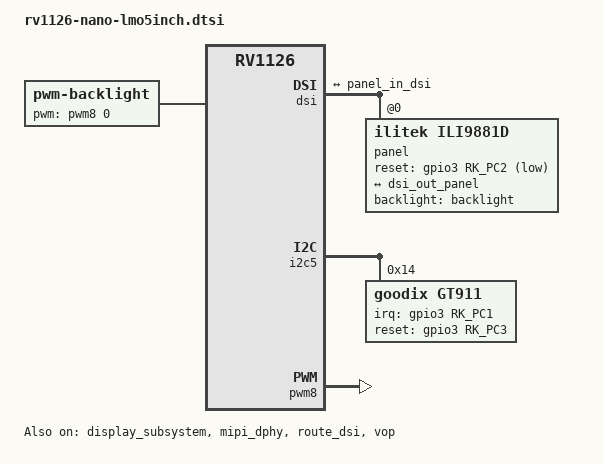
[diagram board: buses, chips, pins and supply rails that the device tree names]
// SPDX-License-Identifier: (GPL-2.0+ OR MIT)
/*
 * Guangzhou Easy EAI Technology Co., Ltd.
 *
 */

#include <dt-bindings/display/drm_mipi_dsi.h>

/ {
	backlight: backlight {
		compatible = "pwm-backlight";
		pwms = <&pwm8 0 25000 0>;
		brightness-levels = <
			  0   1   2   3   4   5   6   7
			  8   9  10  11  12  13  14  15
			 16  17  18  19  20  21  22  23
			 24  25  26  27  28  29  30  31
			 32  33  34  35  36  37  38  39
			 40  41  42  43  44  45  46  47
			 48  49  50  51  52  53  54  55
			 56  57  58  59  60  61  62  63
			 64  65  66  67  68  69  70  71
			 72  73  74  75  76  77  78  79
			 80  81  82  83  84  85  86  87
			 88  89  90  91  92  93  94  95
			 96  97  98  99 100 101 102 103
			104 105 106 107 108 109 110 111
			112 113 114 115 116 117 118 119
			120 121 122 123 124 125 126 127
			128 129 130 131 132 133 134 135
			136 137 138 139 140 141 142 143
			144 145 146 147 148 149 150 151
			152 153 154 155 156 157 158 159
			160 161 162 163 164 165 166 167
			168 169 170 171 172 173 174 175
			176 177 178 179 180 181 182 183
			184 185 186 187 188 189 190 191
			192 193 194 195 196 197 198 199
			200 201 202 203 204 205 206 207
			208 209 210 211 212 213 214 215
			216 217 218 219 220 221 222 223
			224 225 226 227 228 229 230 231
			232 233 234 235 236 237 238 239
			240 241 242 243 244 245 246 247
			248 249 250 251 252 253 254 255>;
		default-brightness-level = <255>;
	};
};

&display_subsystem {
	status = "okay";
};

&dsi {
	status = "okay";

	panel@0 {
		pinctrl-names = "default";
		pinctrl-0 = <&panel_rst>;
		compatible = "ilitek,ili9881d", "simple-panel-dsi";
		reg = <0>;
		backlight = <&backlight>;
		reset-gpios = <&gpio3 RK_PC2 GPIO_ACTIVE_LOW>;
		prepare-delay-ms = <5>;
		reset-delay-ms = <10>;
		init-delay-ms = <120>;

		width-mm = <61>;
		height-mm = <109>;

		dsi,flags = <(MIPI_DSI_MODE_VIDEO | MIPI_DSI_MODE_VIDEO_BURST |
			      MIPI_DSI_MODE_LPM | MIPI_DSI_MODE_EOT_PACKET)>;
		dsi,format = <MIPI_DSI_FMT_RGB888>;
		dsi,lanes = <4>;

		panel-init-sequence = [
			15 00 02 E1 93
			15 00 02 E2 65
			15 00 02 E3 F8
			15 00 02 70 20
			15 00 02 71 13
			15 00 02 72 06
			15 00 02 75 03
			15 00 02 E0 01
			15 00 02 00 00
			15 00 02 01 47
			15 00 02 03 00
			15 00 02 04 4D
			15 00 02 0C 64
			15 00 02 17 00
			15 00 02 18 BF
			15 00 02 19 00
			15 00 02 1A 00
			15 00 02 1B BF
			15 00 02 1C 00
			15 00 02 1F 7E
			15 00 02 20 24
			15 00 02 21 24
			15 00 02 22 4E
			15 00 02 24 FE
			15 00 02 37 09
			15 00 02 38 04
			15 00 02 3C 76
			15 00 02 3D FF
			15 00 02 3E FF
			15 00 02 3F 7F
			15 00 02 40 04
			15 00 02 41 A0
			15 00 02 44 11
			15 00 02 55 02
			15 00 02 56 01
			15 00 02 57 49
			15 00 02 58 09
			15 00 02 59 2A
			15 00 02 5A 1A
			15 00 02 5B 1A
			15 00 02 5D 78
			15 00 02 5E 6E
			15 00 02 5F 66
			15 00 02 60 5E
			15 00 02 61 60
			15 00 02 62 54
			15 00 02 63 5C
			15 00 02 64 47
			15 00 02 65 5F
			15 00 02 66 5D
			15 00 02 67 5B
			15 00 02 68 76
			15 00 02 69 61
			15 00 02 6A 63
			15 00 02 6B 50
			15 00 02 6C 45
			15 00 02 6D 34
			15 00 02 6E 1C
			15 00 02 6F 07
			15 00 02 70 78
			15 00 02 71 6E
			15 00 02 72 66
			15 00 02 73 5E
			15 00 02 74 60
			15 00 02 75 54
			15 00 02 76 5C
			15 00 02 77 47
			15 00 02 78 5F
			15 00 02 79 5D
			15 00 02 7A 5B
			15 00 02 7B 76
			15 00 02 7C 61
			15 00 02 7D 63
			15 00 02 7E 50
			15 00 02 7F 45
			15 00 02 80 34
			15 00 02 81 1C
			15 00 02 82 07
			15 00 02 E0 02
			15 00 02 00 44
			15 00 02 01 46
			15 00 02 02 48
			15 00 02 03 4A
			15 00 02 04 40
			15 00 02 05 42
			15 00 02 06 1F
			15 00 02 07 1F
			15 00 02 08 1F
			15 00 02 09 1F
			15 00 02 0A 1F
			15 00 02 0B 1F
			15 00 02 0C 1F
			15 00 02 0D 1F
			15 00 02 0E 1F
			15 00 02 0F 1F
			15 00 02 10 1F
			15 00 02 11 1F
			15 00 02 12 1F
			15 00 02 13 1F
			15 00 02 14 1E
			15 00 02 15 1F
			15 00 02 16 45
			15 00 02 17 47
			15 00 02 18 49
			15 00 02 19 4B
			15 00 02 1A 41
			15 00 02 1B 43
			15 00 02 1C 1F
			15 00 02 1D 1F
			15 00 02 1E 1F
			15 00 02 1F 1F
			15 00 02 20 1F
			15 00 02 21 1F
			15 00 02 22 1F
			15 00 02 23 1F
			15 00 02 24 1F
			15 00 02 25 1F
			15 00 02 26 1F
			15 00 02 27 1F
			15 00 02 28 1F
			15 00 02 29 1F
			15 00 02 2A 1E
			15 00 02 2B 1F
			15 00 02 2C 0B
			15 00 02 2D 09
			15 00 02 2E 07
			15 00 02 2F 05
			15 00 02 30 03
			15 00 02 31 01
			15 00 02 32 1F
			15 00 02 33 1F
			15 00 02 34 1F
			15 00 02 35 1F
			15 00 02 36 1F
			15 00 02 37 1F
			15 00 02 38 1F
			15 00 02 39 1F
			15 00 02 3A 1F
			15 00 02 3B 1F
			15 00 02 3C 1F
			15 00 02 3D 1F
			15 00 02 3E 1F
			15 00 02 3F 1F
			15 00 02 40 1F
			15 00 02 41 1E
			15 00 02 42 0A
			15 00 02 43 08
			15 00 02 44 06
			15 00 02 45 04
			15 00 02 46 02
			15 00 02 47 00
			15 00 02 48 1F
			15 00 02 49 1F
			15 00 02 4A 1F
			15 00 02 4B 1F
			15 00 02 4C 1F
			15 00 02 4D 1F
			15 00 02 4E 1F
			15 00 02 4F 1F
			15 00 02 50 1F
			15 00 02 51 1F
			15 00 02 52 1F
			15 00 02 53 1F
			15 00 02 54 1F
			15 00 02 55 1F
			15 00 02 56 1F
			15 00 02 57 1E
			15 00 02 58 40
			15 00 02 59 00
			15 00 02 5A 00
			15 00 02 5B 30
			15 00 02 5C 02
			15 00 02 5D 40
			15 00 02 5E 01
			15 00 02 5F 02
			15 00 02 60 00
			15 00 02 61 01
			15 00 02 62 02
			15 00 02 63 65
			15 00 02 64 66
			15 00 02 65 00
			15 00 02 66 00
			15 00 02 67 74
			15 00 02 68 06
			15 00 02 69 65
			15 00 02 6A 66
			15 00 02 6B 10
			15 00 02 6C 00
			15 00 02 6D 04
			15 00 02 6E 04
			15 00 02 6F 88
			15 00 02 70 00
			15 00 02 71 00
			15 00 02 72 06
			15 00 02 73 7B
			15 00 02 74 00
			15 00 02 75 87
			15 00 02 76 00
			15 00 02 77 5D
			15 00 02 78 17
			15 00 02 79 1F
			15 00 02 7A 00
			15 00 02 7B 00
			15 00 02 7C 00
			15 00 02 7D 03
			15 00 02 7E 7B
			15 00 02 E0 04
			15 00 02 09 10
			15 00 02 E0 00
			15 00 02 E6 02
			15 00 02 E7 02
			05 C8 01 11
			05 14 01 29
			15 00 02 35 00
		];

		panel-exit-sequence = [
			15 00 02 28 00
			15 00 02 10 00
		];

		display-timings {
			native-mode = <&timing0>;

			timing0: timing0 {
				clock-frequency = <62000000>;
				hactive = <720>;
				vactive = <1280>;
				hfront-porch = <30>;
				hsync-len = <20>;
				hback-porch = <20>;
				vfront-porch = <8>;
				vsync-len = <2>;
				vback-porch = <16>;
				hsync-active = <0>;
				vsync-active = <0>;
				de-active = <0>;
				pixelclk-active = <0>;
			};
		};

		ports {
			#address-cells = <1>;
			#size-cells = <0>;

			port@0 {
				reg = <0>;
				panel_in_dsi: endpoint {
					remote-endpoint = <&dsi_out_panel>;
				};
			};
		};
	};

	ports {
		#address-cells = <1>;
		#size-cells = <0>;

		port@1 {
			reg = <1>;
			dsi_out_panel: endpoint {
				remote-endpoint = <&panel_in_dsi>;
			};
		};
	};
};

&i2c5 {
	status = "okay";
	pinctrl-0 = <&i2c5m1_xfer>;

	gt911@14 {
		pinctrl-names = "default";
		pinctrl-0 = <&touch_rst &touch_irq>;
		compatible = "goodix,gt911";
		reg = <0x14>;
		interrupt-parent = <&gpio3>;
		interrupts = <RK_PC1 0>;

		irq-gpios = <&gpio3 RK_PC1 0>;
		reset-gpios = <&gpio3 RK_PC3 0>;
		touchscreen-inverted-x;
		touchscreen-inverted-y;
	};
};

&mipi_dphy {
	status = "okay";
};

&pinctrl {
	mipi-dsi {
		/omit-if-no-ref/
		panel_rst: panel_rst {
			rockchip,pins =
				<3 RK_PC2 RK_FUNC_GPIO &pcfg_pull_up>;
		};
	};

	touch-screen {
		/omit-if-no-ref/
		touch_rst: touch_rst {
			rockchip,pins =
				<3 RK_PC3 RK_FUNC_GPIO &pcfg_pull_up>;
		};

		/omit-if-no-ref/
		touch_irq: touch_irq {
			rockchip,pins =
				<3 RK_PC1 RK_FUNC_GPIO &pcfg_pull_up>;
		};
	};
};

&pwm8 {
	status = "okay";
	pinctrl-0 = <&pwm8m1_pins>;
};

&route_dsi {
	status = "okay";
};

&vop {
	status = "okay";
};

&vop_mmu {
	status = "okay";
};
